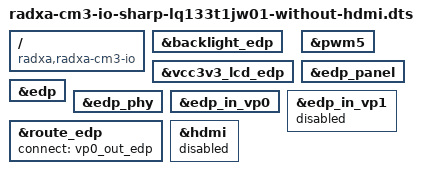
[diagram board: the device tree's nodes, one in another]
/dts-v1/;
/plugin/;

/ {
	compatible = "radxa,radxa-cm3-io", "rockchip,rk3566";

	fragment@0 {
		target = <&backlight_edp>;

		__overlay__ {
			status = "okay";
		};
	};

	fragment@1 {
		target = <&vcc3v3_lcd_edp>;

		__overlay__ {
			status = "okay";
		};
	};

	fragment@2 {
		target = <&pwm5>;

		__overlay__ {
			status = "okay";
		};
	};

	fragment@3 {
		target = <&edp_panel>;

		__overlay__ {
			status = "okay";
		};
	};

	fragment@4 {
		target = <&edp>;

		__overlay__ {
			status = "okay";
		};
	};

	fragment@5 {
		target = <&edp_phy>;

		__overlay__ {
			status = "okay";
		};
	};

	fragment@6 {
		target = <&edp_in_vp0>;

		__overlay__ {
			status = "okay";
		};
	};

	fragment@7 {
		target = <&edp_in_vp1>;

		__overlay__ {
			status = "disabled";
		};
	};

	fragment@8 {
		target = <&route_edp>;

		__overlay__ {
			status = "okay";
			connect = <&vp0_out_edp>;
		};
	};

	fragment@9 {
		target = <&hdmi>;

		__overlay__ {
			status = "disabled";
		};
	};
};
